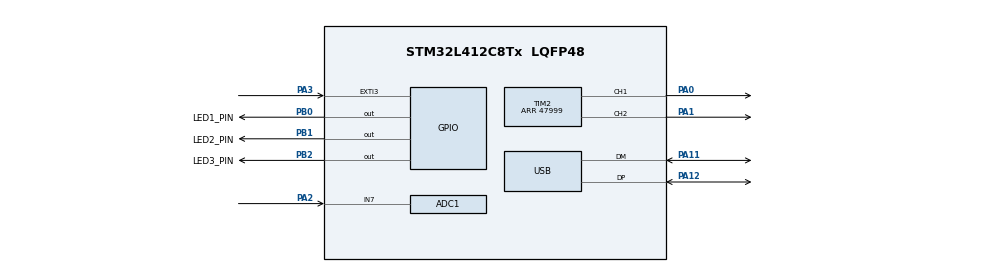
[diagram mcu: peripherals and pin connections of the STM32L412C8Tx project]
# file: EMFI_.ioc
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ADC1.Channel-0\#ChannelRegularConversion=ADC_CHANNEL_7
ADC1.ContinuousConvMode=ENABLE
ADC1.DMAContinuousRequests=ENABLE
ADC1.NbrOfConversionFlag=1
ADC1.OffsetNumber-0\#ChannelRegularConversion=ADC_OFFSET_NONE
ADC1.Rank-0\#ChannelRegularConversion=1
ADC1.SamplingTime-0\#ChannelRegularConversion=ADC_SAMPLETIME_2CYCLES_5
ADC1.master=1
Dma.ADC1.0.Direction=DMA_PERIPH_TO_MEMORY
Dma.ADC1.0.Instance=DMA1_Channel1
Dma.ADC1.0.MemDataAlignment=DMA_MDATAALIGN_HALFWORD
Dma.ADC1.0.MemInc=DMA_MINC_ENABLE
Dma.ADC1.0.Mode=DMA_NORMAL
Dma.ADC1.0.PeriphDataAlignment=DMA_PDATAALIGN_HALFWORD
Dma.ADC1.0.PeriphInc=DMA_PINC_DISABLE
Dma.ADC1.0.Priority=DMA_PRIORITY_LOW
Dma.Request0=ADC1
Mcu.Family=STM32L4
Mcu.Name=STM32L412C8Tx
Mcu.Package=LQFP48
NVIC.ADC1_2_IRQn=true\:0\:0\:false\:false\:true\:true\:true\:true
NVIC.DMA1_Channel1_IRQn=true\:0\:0\:false\:false\:true\:false\:true\:true
NVIC.PriorityGroup=NVIC_PRIORITYGROUP_4
NVIC.TIM6_IRQn=true\:0\:0\:false\:false\:true\:true\:true\:true
NVIC.USB_IRQn=true\:0\:0\:false\:false\:true\:false\:true\:true
PA0.Signal=S_TIM2_CH1
PA1.Signal=S_TIM2_CH2
PA11.Mode=Device
PA11.Signal=USB_DM
PA12.Mode=Device
PA12.Signal=USB_DP
PA2.Signal=ADCx_IN7
PA3.Signal=GPXTI3
PB0.GPIO_Label=LED1_PIN
PB0.Signal=GPIO_Output
PB1.GPIO_Label=LED2_PIN
PB1.Signal=GPIO_Output
PB2.GPIO_Label=LED3_PIN
PB2.Signal=GPIO_Output
ProjectManager.HeapSize=0x200
ProjectManager.StackSize=0x400
ProjectManager.TargetToolchain=STM32CubeIDE
RCC.ADCFreq_Value=48000000
RCC.AHBFreq_Value=48000000
RCC.APB1Freq_Value=48000000
RCC.APB1TimFreq_Value=48000000
RCC.APB2Freq_Value=48000000
RCC.APB2TimFreq_Value=48000000
RCC.CortexFreq_Value=48000000
RCC.HCLKFreq_Value=48000000
RCC.HSE_VALUE=8000000
RCC.HSI48_VALUE=48000000
RCC.HSI_VALUE=16000000
RCC.LSE_VALUE=32768
RCC.MSIClockRange=RCC_MSIRANGE_11
RCC.MSI_VALUE=48000000
RCC.PLLSourceVirtual=RCC_PLLSOURCE_HSI
RCC.SYSCLKFreq_VALUE=48000000
RCC.USBFreq_Value=48000000
RCC.VCOOutputFreq_Value=128000000
SH.ADCx_IN7.0=ADC1_IN7,IN7-Single-Ended
SH.S_TIM2_CH1.0=TIM2_CH1,PWM Generation1 CH1
SH.S_TIM2_CH2.0=TIM2_CH2,PWM Generation2 CH2
TIM2.AutoReloadPreload=TIM_AUTORELOAD_PRELOAD_ENABLE
TIM2.Channel-PWM\ Generation1\ CH1=TIM_CHANNEL_1
TIM2.Channel-PWM\ Generation2\ CH2=TIM_CHANNEL_2
TIM2.Period=47999
TIM6.AutoReloadPreload=TIM_AUTORELOAD_PRELOAD_ENABLE
TIM6.Period=47999
USB_DEVICE.CLASS_NAME_FS=CDC
USB_DEVICE.VirtualMode=Cdc
USB_DEVICE.VirtualModeFS=Cdc_FS
VP_TIM2_VS_ClockSourceINT.Mode=Internal
VP_TIM6_VS_ClockSourceINT.Mode=Enable_Timer
VP_USB_DEVICE_VS_USB_DEVICE_CDC_FS.Mode=CDC_FS
board=custom

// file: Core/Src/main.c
/* USER CODE BEGIN Header */
/**
  ******************************************************************************
  * @file           : main.c
  * @brief          : Main program body
  ******************************************************************************
  * @attention
  *
  * Copyright (c) 2023 STMicroelectronics.
  * All rights reserved.
  *
  * This software is licensed under terms that can be found in the LICENSE file
  * in the root directory of this software component.
  * If no LICENSE file comes with this software, it is provided AS-IS.
  *
  ******************************************************************************
  */
/* USER CODE END Header */
#include "main.h"
#include "usb_device.h"
#include "board.h"

int main(void)
{

  /* MCU Configuration--------------------------------------------------------*/

  /* Reset of all peripherals, Initializes the Flash interface and the Systick. */
  HAL_Init();

  /* Configure the system clock */
  SystemClock_Config();

  /* Initialize all configured peripherals */
  MX_GPIO_Init();
  MX_DMA_Init();
  MX_ADC1_Init();
  MX_TIM2_Init();
  MX_TIM6_Init();
  MX_USB_DEVICE_Init();
  /* USER CODE BEGIN 2 */

  BSP_TIM_PWM_CH1_Start();
  BSP_TIM_PWM_CH2_Start();

  HAL_Delay(1);
  LED_TWO_ON;

 // HAL_ADCEx_Calibration_Start(&hadc1);

  /* USER CODE END 2 */

  /* Infinite loop */
  /* USER CODE BEGIN WHILE */
  while (1)
  {
	  HAL_Delay(1);
	  BSP_Start_ADC_IT();

    /* USER CODE END WHILE */

  }
}

void Error_Handler(void)
{
  __disable_irq();
  while (1)
  {
  }
}
